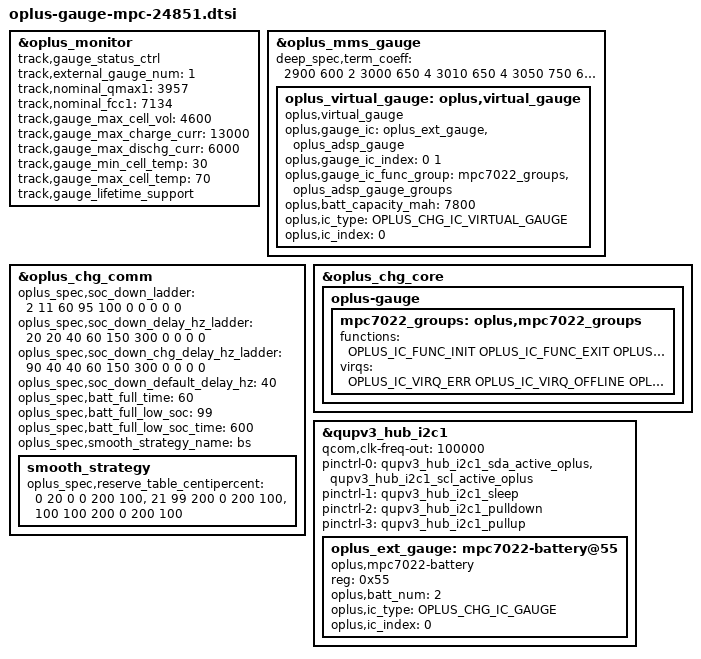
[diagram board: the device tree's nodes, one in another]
/* BQ MPC pack gauge */
#define GAUGE_HX_MPC7022 4
#include "oplus-chg-24851.dtsi"

&oplus_monitor {
	track,gauge_status_ctrl;
	track,external_gauge_num = <1>;
	track,nominal_qmax1 = <3957>;
	track,nominal_fcc1 = <7134>;

	track,gauge_max_cell_vol = <4600>;
	track,gauge_max_charge_curr = <13000>;
	track,gauge_max_dischg_curr = <6000>;
	track,gauge_min_cell_temp = <30>;
	track,gauge_max_cell_temp = <70>;
	track,gauge_lifetime_support;
};

&oplus_mms_gauge {
	deep_spec,term_coeff = <2900 600 2
				3000 650 4
				3010 650 4
				3050 750 6
				3100 800 8
				3110 800 8
				3150 900 10
				3160 900 10
				3200 1000 12
				3210 1000 12
				3260 1100 12>;
	oplus_virtual_gauge: oplus,virtual_gauge {
		compatible = "oplus,virtual_gauge";
		oplus,gauge_ic = <&oplus_ext_gauge  &oplus_adsp_gauge>;
		oplus,gauge_ic_index = <0 1>;
		oplus,gauge_ic_func_group = <&mpc7022_groups &oplus_adsp_gauge_groups>;
		oplus,batt_capacity_mah = <7800>;
		oplus,ic_type = <OPLUS_CHG_IC_VIRTUAL_GAUGE>;
		oplus,ic_index = <0>;
	};
};

&oplus_chg_comm {
	oplus_spec,soc_down_ladder = <2 11 60 95 100 0 0 0 0 0>;
	oplus_spec,soc_down_delay_hz_ladder = <20 20 40 60 150 300 0 0 0 0>;
	oplus_spec,soc_down_chg_delay_hz_ladder = <90 40 40 60 150 300 0 0 0 0>;
	oplus_spec,soc_down_default_delay_hz = <40>;

	oplus_spec,batt_full_time = <60>;
	oplus_spec,batt_full_low_soc = <99>;
	oplus_spec,batt_full_low_soc_time = <600>;
	oplus_spec,smooth_strategy_name = "bs";
	smooth_strategy {
		oplus_spec,reserve_table_centipercent =
			/* start(%) end(%) dischg_reserve(0.01%) full_reserve(0.01%) chg_reserve(0.01%) chg_split(%) */
			<0   20  0   0   200 100>,
			<21  99  200 0   200 100>,
			<100 100 200 0   200 100>;
	};
};

&oplus_chg_core {
	oplus-gauge {
		mpc7022_groups: oplus,mpc7022_groups {
			functions = <
				OPLUS_IC_FUNC_INIT
				OPLUS_IC_FUNC_EXIT
				OPLUS_IC_FUNC_GAUGE_GET_BATT_VOL
				OPLUS_IC_FUNC_GAUGE_GET_BATT_MAX
				OPLUS_IC_FUNC_GAUGE_GET_BATT_MIN
				OPLUS_IC_FUNC_GAUGE_GET_BATT_CURR
				OPLUS_IC_FUNC_GAUGE_GET_BATT_TEMP
				OPLUS_IC_FUNC_GAUGE_GET_BATT_SOC
				OPLUS_IC_FUNC_GAUGE_GET_BATT_FCC
				OPLUS_IC_FUNC_GAUGE_GET_BATT_CC
				OPLUS_IC_FUNC_GAUGE_GET_BATT_RM
				OPLUS_IC_FUNC_GAUGE_GET_BATT_SOH
				OPLUS_IC_FUNC_GAUGE_GET_BATT_AUTH
				OPLUS_IC_FUNC_GAUGE_GET_BATT_HMAC
				OPLUS_IC_FUNC_GAUGE_GET_BATT_NUM
				OPLUS_IC_FUNC_GAUGE_GET_DEVICE_TYPE
				OPLUS_IC_FUNC_GAUGE_IS_SUSPEND
				OPLUS_IC_FUNC_GAUGE_GET_DEVICE_TYPE_FOR_BCC
				OPLUS_IC_FUNC_GAUGE_GET_DOD0
				OPLUS_IC_FUNC_GAUGE_GET_DOD0_PASSED_Q
				OPLUS_IC_FUNC_GAUGE_GET_QMAX
				OPLUS_IC_FUNC_GAUGE_GET_QMAX_PASSED_Q
				OPLUS_IC_FUNC_GAUGE_GET_DEEP_DISCHG_COUNT
				OPLUS_IC_FUNC_GAUGE_SET_DEEP_DISCHG_COUNT
				OPLUS_IC_FUNC_GAUGE_SET_DEEP_TERM_VOLT
				OPLUS_IC_FUNC_GAUGE_GET_REG_INFO
				OPLUS_IC_FUNC_GAUGE_GET_CALIB_TIME
				OPLUS_IC_FUNC_GAUGE_GET_DEEP_TERM_VOLT
				OPLUS_IC_FUNC_GAUGE_SET_LAST_CC
				OPLUS_IC_FUNC_GAUGE_GET_LAST_CC
				OPLUS_IC_FUNC_GAUGE_GET_SILI_LIFETIME_STATUS
				OPLUS_IC_FUNC_GAUGE_GET_SILI_LIFETIME_INFO
				OPLUS_IC_FUNC_GAUGE_SET_CALIB_TIME
				OPLUS_IC_FUNC_GAUGE_GET_BATT_SN
				OPLUS_IC_FUNC_GAUGE_GET_FIRST_USAGE_DATE
				OPLUS_IC_FUNC_GAUGE_SET_FIRST_USAGE_DATE
				OPLUS_IC_FUNC_GAUGE_GET_UI_CC
				OPLUS_IC_FUNC_GAUGE_SET_UI_CC
				OPLUS_IC_FUNC_GAUGE_GET_UI_SOH
				OPLUS_IC_FUNC_GAUGE_SET_UI_SOH
				OPLUS_IC_FUNC_GAUGE_GET_USED_FLAG
				OPLUS_IC_FUNC_GAUGE_SET_USED_FLAG
				OPLUS_IC_FUNC_GAUGE_GET_MANU_DATE
				OPLUS_IC_FUNC_GAUGE_GET_GAUGE_CAR_C
				/*TODO: remove the battery full to fix the issue of force report full*/
				/*OPLUS_IC_FUNC_GAUGE_SET_BATT_FULL*/
				OPLUS_IC_FUNC_GAUGE_SET_CUV_STATE
				OPLUS_IC_FUNC_GAUGE_GET_CUV_STATE
				OPLUS_IC_FUNC_GAUGE_GET_BATT_SOC_CENTI
			>;
			virqs = <
				OPLUS_IC_VIRQ_ERR
				OPLUS_IC_VIRQ_OFFLINE
				OPLUS_IC_VIRQ_RESUME
			>;
		};
	};
};

&qupv3_hub_i2c1 {
	status = "ok";
	qcom,clk-freq-out = <100000>;
	pinctrl-names = "default", "sleep", "pulldown", "pullup";
	pinctrl-0 = <&qupv3_hub_i2c1_sda_active_oplus>, <&qupv3_hub_i2c1_scl_active_oplus>;
	pinctrl-1 = <&qupv3_hub_i2c1_sleep>;
	pinctrl-2 = <&qupv3_hub_i2c1_pulldown>;
	pinctrl-3 = <&qupv3_hub_i2c1_pullup>;

	oplus_ext_gauge: mpc7022-battery@55 {
		status = "okay";
		compatible = "oplus,mpc7022-battery";
		reg = <0x55>;

		oplus,batt_num = <2>;
		oplus,ic_type = <OPLUS_CHG_IC_GAUGE>;
		oplus,ic_index = <0>;
	};
};
